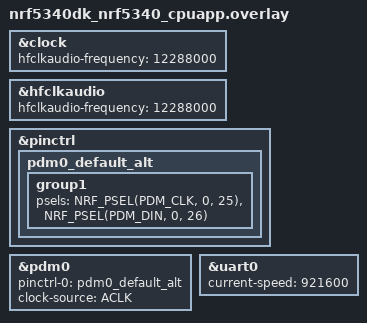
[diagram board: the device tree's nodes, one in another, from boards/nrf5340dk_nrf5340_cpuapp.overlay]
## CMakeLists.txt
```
# SPDX-License-Identifier: LicenseRef-Nordic-5-Clause

cmake_minimum_required(VERSION 3.20.0)

find_package(Zephyr REQUIRED HINTS $ENV{ZEPHYR_BASE})
project(dmic)

target_sources(app PRIVATE src/main.c)
if(CONFIG_SOC_NRF54H20_IRON)
  target_sources(app PRIVATE periphconf_migrated_src/periphconf_migrated_from_uicr.c)
endif()
```

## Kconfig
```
#
# Copyright (c) 2025 Nordic Semiconductor ASA
#
# SPDX-License-Identifier: LicenseRef-Nordic-5-Clause
#

source "Kconfig.zephyr"

config TEST_USE_DMM
	bool "Use of DMM pre-allocation"
	help
	  The test will use it to determine whether to prealocate DMM
	  buffer or use regular mem slab and allocate dmm buffer inside
	  PDM driver.

config TEST_STEREO_CONFIGURATION
	bool "Select mono / stereo operation"
	help
	  When set to 'y' PDM driver will be configured in stereo mode.
	  In such case, import RAW audio data using following configuration:
	  Signed 16-bit PCM; little-endian; stereo; 16000Hz.
```

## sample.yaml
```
sample:
  name: DMIC sample
tests:
  sample.drivers.audio.dmic_dump_buffer:
    tags: dmic
    filter: dt_nodelabel_enabled("dmic_dev")
    integration_platforms:
      - nrf52840dk/nrf52840
      - nrf5340dk/nrf5340/cpuapp
      - nrf54l15dk/nrf54l15/cpuapp
    harness: console
    harness_config:
      type: multi_line
      ordered: true
      regex:
        - "DMIC sample"
        - "Exiting"
```

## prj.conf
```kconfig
CONFIG_BOOT_BANNER=n
CONFIG_NCS_BOOT_BANNER=n

CONFIG_AUDIO=y
CONFIG_AUDIO_DMIC=y

CONFIG_LOG=n
CONFIG_LOG_MODE_IMMEDIATE=n
CONFIG_PRINTK=y

CONFIG_MAIN_STACK_SIZE=16384
```

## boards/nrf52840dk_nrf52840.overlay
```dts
/*
 * Copyright (c) 2025 Nordic Semiconductor ASA
 *
 * SPDX-License-Identifier: LicenseRef-Nordic-5-Clause
 */

&pinctrl {
	pdm0_default_alt: pdm0_default_alt {
		group1 {
			psels = <NRF_PSEL(PDM_CLK, 0, 30)>,
				<NRF_PSEL(PDM_DIN, 0, 31)>;
		};
	};
};

dmic_dev: &pdm0 {
	status = "okay";
	pinctrl-0 = <&pdm0_default_alt>;
	pinctrl-names = "default";
	clock-source = "PCLK32M_HFXO";
};

&uart0 {
	current-speed = <921600>;
};
```

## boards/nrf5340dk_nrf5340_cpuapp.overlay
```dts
/*
 * Copyright (c) 2025 Nordic Semiconductor ASA
 *
 * SPDX-License-Identifier: LicenseRef-Nordic-5-Clause
 */

&clock {
	hfclkaudio-frequency = <12288000>;
};

&hfclkaudio {
	hfclkaudio-frequency = <12288000>;
};

&pinctrl {
	pdm0_default_alt: pdm0_default_alt {
		group1 {
			psels = <NRF_PSEL(PDM_CLK, 0, 25)>,
				<NRF_PSEL(PDM_DIN, 0, 26)>;
		};
	};
};

dmic_dev: &pdm0 {
	status = "okay";
	pinctrl-0 = <&pdm0_default_alt>;
	pinctrl-names = "default";
	clock-source = "ACLK";
};

&uart0 {
	current-speed = <921600>;
};
```

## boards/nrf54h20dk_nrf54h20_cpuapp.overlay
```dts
/*
 * Copyright (c) 2025 Nordic Semiconductor ASA
 *
 * SPDX-License-Identifier: LicenseRef-Nordic-5-Clause
 */

&pinctrl {
	pdm0_default_alt: pdm0_default_alt {
		group1 {
			psels = <NRF_PSEL(PDM_CLK, 1, 2)>,
				<NRF_PSEL(PDM_DIN, 1, 4)>;
		};
	};
};

dmic_dev: &pdm0 {
	status = "okay";
	pinctrl-0 = <&pdm0_default_alt>;
	pinctrl-names = "default";
	clock-source = "PCLK32M";
	memory-regions = <&cpuapp_dma_region>;
};

&uart136 {
	current-speed = <921600>;
};
```

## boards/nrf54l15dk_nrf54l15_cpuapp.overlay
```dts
/*
 * Copyright (c) 2025 Nordic Semiconductor ASA
 *
 * SPDX-License-Identifier: LicenseRef-Nordic-5-Clause
 */

&pinctrl {
	pdm20_default_alt: pdm20_default_alt {
		group1 {
			psels = <NRF_PSEL(PDM_CLK, 1, 12)>,
				<NRF_PSEL(PDM_DIN, 1, 13)>;
		};
	};
};

dmic_dev: &pdm20 {
	status = "okay";
	pinctrl-0 = <&pdm20_default_alt>;
	pinctrl-names = "default";
	clock-source = "PCLK32M";
};

&uart20 {
	current-speed = <921600>;
};
```

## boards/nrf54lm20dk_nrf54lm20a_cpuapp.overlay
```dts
/*
 * Copyright (c) 2026 Nordic Semiconductor ASA
 *
 * SPDX-License-Identifier: LicenseRef-Nordic-5-Clause
 */

&pinctrl {
	pdm20_default_alt: pdm20_default_alt {
		group1 {
			psels = <NRF_PSEL(PDM_CLK, 1, 23)>,
				<NRF_PSEL(PDM_DIN, 1, 14)>;
		};
	};
};

dmic_dev: &pdm20 {
	status = "okay";
	pinctrl-0 = <&pdm20_default_alt>;
	pinctrl-names = "default";
	clock-source = "PCLK32M";
};

&uart20 {
	current-speed = <921600>;
};
```

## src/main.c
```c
/*
 * Copyright (c) 2025 Nordic Semiconductor ASA
 *
 * SPDX-License-Identifier: LicenseRef-Nordic-5-Clause
 */

#include <string.h>
#include <zephyr/kernel.h>
#include <zephyr/audio/dmic.h>

#if defined(CONFIG_HAS_NORDIC_DMM)
#include <dmm.h>
#endif

#include <zephyr/logging/log.h>
LOG_MODULE_REGISTER(dmic_sample);

#define SAMPLE_RATE  16000
#define SAMPLE_BIT_WIDTH 16
#define BYTES_PER_SAMPLE (SAMPLE_BIT_WIDTH / 8)
#define NO_OF_CHANNELS	1

/* Milliseconds to wait for a block to be captured by PCM peripheral. */
#define READ_TIMEOUT     1200

/* Driver will allocate blocks from this slab to receive audio data into them.
 * Application, after getting a given block from the driver and processing its
 * data, needs to free that block.
 */
#define AUDIO_BLOCK_SIZE   (BYTES_PER_SAMPLE * SAMPLE_RATE * NO_OF_CHANNELS / 40)
/* Driver allocates memory "in advance" therefore 2 blocks may be not enough. */
#define BLOCK_COUNT      4

#if CONFIG_TEST_USE_DMM
struct k_mem_slab mem_slab;
char __aligned(WB_UP(4)) mem_slab_buffer[BLOCK_COUNT * WB_UP(AUDIO_BLOCK_SIZE)]
					 DMM_MEMORY_SECTION(DT_NODELABEL(dmic_dev));
#else
K_MEM_SLAB_DEFINE_STATIC(mem_slab, AUDIO_BLOCK_SIZE, BLOCK_COUNT, 4);
#endif

int main(void)
{
	const struct device *const dmic_dev = DEVICE_DT_GET(DT_NODELABEL(dmic_dev));
	int ret;
	int loop_counter = 1;
	void *buffer;
	uint32_t size;

	struct pcm_stream_cfg stream = {
		.pcm_rate = SAMPLE_RATE,
		.pcm_width = SAMPLE_BIT_WIDTH,
		.block_size = AUDIO_BLOCK_SIZE,
		.mem_slab  = &mem_slab,
	};

	struct dmic_cfg cfg = {
		.io = {
			/* These fields can be used to limit the PDM clock
			 * configurations that the driver is allowed to use
			 * to those supported by the microphone.
			 */
			.min_pdm_clk_freq = 1000000,
			.max_pdm_clk_freq = 3250000,
			.min_pdm_clk_dc   = 40,
			.max_pdm_clk_dc   = 60,
		},
		.streams = &stream,
		.channel = {
			.req_num_streams = 1,
#if defined(CONFIG_TEST_STEREO_CONFIGURATION)
			.req_num_chan = 2,
			.req_chan_map_lo =
				dmic_build_channel_map(0, 0, PDM_CHAN_LEFT) |
				dmic_build_channel_map(1, 0, PDM_CHAN_RIGHT),
#else
			.req_num_chan = 1,
			.req_chan_map_lo = dmic_build_channel_map(0, 0, PDM_CHAN_LEFT),
#endif
		},
	};

	if (!device_is_ready(dmic_dev)) {
		LOG_ERR("%s is not ready", dmic_dev->name);
		return 0;
	}

#if CONFIG_TEST_USE_DMM
	ret = k_mem_slab_init(&mem_slab, mem_slab_buffer, WB_UP(AUDIO_BLOCK_SIZE), BLOCK_COUNT);
	if (ret < 0) {
		LOG_ERR("Memory slab initialization failed, return code = %d", ret);
		return ret;
	}
#endif

	ret = dmic_configure(dmic_dev, &cfg);
	if (ret < 0) {
		LOG_ERR("Failed to configure the driver: %d", ret);
		return ret;
	}

	ret = dmic_trigger(dmic_dev, DMIC_TRIGGER_START);
	if (ret < 0) {
		LOG_ERR("START trigger failed: %d", ret);
		return ret;
	}

	while (1) {
		ret = dmic_read(dmic_dev, 0, &buffer, &size, READ_TIMEOUT);
		if (ret < 0) {
			LOG_ERR("%d - read failed: %d", loop_counter, ret);
			return ret;
		}

		/* Print buffer on serial port (in binary mode). */
		unsigned char pcm_l, pcm_h;
		int j;

		uint16_t *pcm_out = buffer;

		for (j = 0; j < size/2; j++) {
			pcm_l = (char)(pcm_out[j] & 0xFF);
			pcm_h = (char)((pcm_out[j] >> 8) & 0xFF);

			z_impl_k_str_out(&pcm_l, 1);
			z_impl_k_str_out(&pcm_h, 1);
		}

		k_mem_slab_free(&mem_slab, buffer);

		loop_counter++;
	}

	/* Dead code; left for reference. */
	ret = dmic_trigger(dmic_dev, DMIC_TRIGGER_STOP);
	if (ret < 0) {
		LOG_ERR("STOP trigger failed: %d", ret);
		return ret;
	}

	return 0;
}
```
